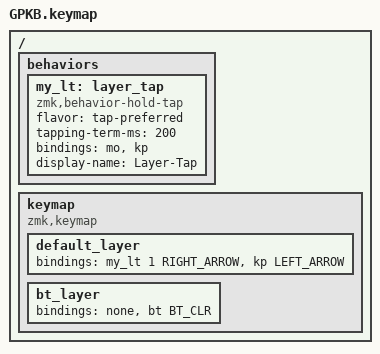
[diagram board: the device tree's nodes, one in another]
#include <behaviors.dtsi>
#include <dt-bindings/zmk/keys.h>
#include <dt-bindings/zmk/bt.h>
#include <dt-bindings/zmk/behaviors.h>

/ {
    behaviors {
        my_lt: layer_tap {
            compatible = "zmk,behavior-hold-tap";
            #binding-cells = <2>;
            flavor = "tap-preferred";
            tapping-term-ms = <200>;
            bindings = <&mo>, <&kp>;
            display-name = "Layer-Tap";
        };
    };
};
/ {
    keymap {
      compatible = "zmk,keymap";
      
        default_layer {
        bindings = <
          &my_lt 1 RIGHT_ARROW
          &kp LEFT_ARROW
        >;
};

    bt_layer {
        bindings = <
        &none
        &bt BT_CLR
      >;
};
};
};
